AUTOSAR XML (schema 00044)
package /E40_Platform_System_SystemPackage/Components
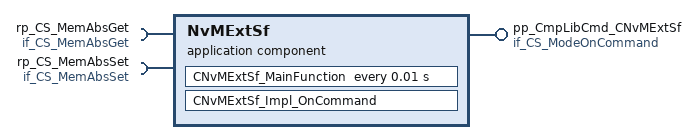
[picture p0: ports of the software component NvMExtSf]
  application sw component type NvMExtSf
    provide port pp_CmpLibCmd_CNvMExtSf: server-com-spec{operation=Impl_OnCommand, queue-length=1}, provided-interface=if_CS_ModeOnCommand
    require port rp_CS_MemAbsGet: required-com-specs=[Get_BsConst_Audio_Element, Get_BsConst_Communication_Element, Get_BsConst_EngOffTimer_Element, Get_BsConst_FuelGauge_Element, Get_BsConst_OilGauge_Element, Get_BsConst_PowerGauge_Element, Get_BsConst_Power_Element, Get_BsConst_RealTimeClock_Element, Get_BsConst_ServiceReminder_Element, Get_BsConst_SpeedoGauge_Element, Get_BsConst_TachoGauge_Element, Get_BsConst_TempGauge_Element, Get_BsConst_TripComputer_Element, Get_BsConst_Warning_Element, Get_BsCys_Certicificate_Element, Get_BsDiag_Dtc_Element, Get_BsDiag_ErrorRecord_Element, Get_BsReten_Audio_Element, Get_BsReten_Communication_Element, Get_BsReten_Display_Element, Get_BsReten_Gauges_Element, Get_BsReten_Illumination_Element, Get_BsReten_Odometer_Element, Get_BsReten_Personalization_Element, Get_BsReten_Power_Element, Get_BsReten_RealTimeClock_Element, Get_BsReten_Tripcomputer_Element, Get_BsReten_Warning_Element, Get_BsRt_CusDlt_Element, Get_BsRt_FuelGauge_Element, Get_BsRt_Illumination_Element, Get_BsRt_Odometer_Element, Get_BsRt_OilGauge_Element, Get_BsRt_Personalization_Element, Get_BsRt_PowerGauge_Element, Get_BsRt_RealTimeClock_Element, Get_BsRt_SpeedoGauge_Element, Get_BsRt_TachoGauge_Element, Get_BsRt_TempGauge_Element, Get_BsRt_TripComputer_Element, Get_BsRt_Warning_Element, Get_BsShare_EcuPartNumber_Element, Get_BsShare_SwUpdFotaFinPrint_Element, Get_BsShare_SwUpdFotaMode_Element, Get_BsShare_SwUpdFotaStatus_Element, Get_BsShare_SwUpdFotadecrypt_Element, Get_BsShare_SwUpdReflash_Element, Get_BsShare_VehicleConfig_Element, Get_BsShare_VisMeet_Element, Get_RefCys_Certicificate1_Element, Get_RefCys_Certicificate_Element, Get_BsShare_VisMeet_EOLEntry_Element, Get_BsShare_AssemblyManufacturingDate, Get_BsShare_AssemblyPlantNumber, Get_BsShare_HWModification, Get_BsShare_PCBSerialNumber, Get_BsShare_ProductSerialNumber, Get_BsShare_SMTManufacturingDate, Get_BsShare_SMTPlantNumber, Get_BsShare_VisteonPCBPartNumber, Get_BsShare_VisteonPartNumber], required-interface=if_CS_MemAbsGet
    require port rp_CS_MemAbsSet: required-com-specs=[Set_BsConst_Audio_Element, Set_BsConst_Communication_Element, Set_BsConst_EngOffTimer_Element, Set_BsConst_FuelGauge_Element, Set_BsConst_OilGauge_Element, Set_BsConst_PowerGauge_Element, Set_BsConst_Power_Element, Set_BsConst_RealTimeClock_Element, Set_BsConst_ServiceReminder_Element, Set_BsConst_SpeedoGauge_Element, Set_BsConst_TachoGauge_Element, Set_BsConst_TempGauge_Element, Set_BsConst_TripComputer_Element, Set_BsConst_Warning_Element, Set_BsCys_Certicificate_Element, Set_BsDiag_Dtc_Element, Set_BsDiag_ErrorRecord_Element, Set_BsReten_Audio_Element, Set_BsReten_Communication_Element, Set_BsReten_Display_Element, Set_BsReten_Gauges_Element, Set_BsReten_Illumination_Element, Set_BsReten_Odometer_Element, Set_BsReten_Personalization_Element, Set_BsReten_Power_Element, Set_BsReten_RealTimeClock_Element, Set_BsReten_Tripcomputer_Element, Set_BsReten_Warning_Element, Set_BsRt_CusDlt_Element, Set_BsRt_FuelGauge_Element, Set_BsRt_Illumination_Element, Set_BsRt_Odometer_Element, Set_BsRt_OilGauge_Element, Set_BsRt_Personalization_Element, Set_BsRt_PowerGauge_Element, Set_BsRt_RealTimeClock_Element, Set_BsRt_SpeedoGauge_Element, Set_BsRt_TachoGauge_Element, Set_BsRt_TempGauge_Element, Set_BsRt_TripComputer_Element, Set_BsRt_Warning_Element, Set_BsShare_EcuPartNumber_Element, Set_BsShare_SwUpdFotaFinPrint_Element, Set_BsShare_SwUpdFotaMode_Element, Set_BsShare_SwUpdFotaStatus_Element, Set_BsShare_SwUpdFotadecrypt_Element, Set_BsShare_SwUpdReflash_Element, Set_BsShare_VehicleConfig_Element, Set_BsShare_VisMeet_Element, Set_RefCys_Certicificate1_Element, Set_RefCys_Certicificate_Element, Set_BsShare_VisMeet_EOLEntry_Element, Set_BsShare_AssemblyManufacturingDate, Set_BsShare_AssemblyPlantNumber, Set_BsShare_HWModification, Set_BsShare_PCBSerialNumber, Set_BsShare_ProductSerialNumber, Set_BsShare_SMTManufacturingDate, Set_BsShare_SMTPlantNumber, Set_BsShare_VisteonPCBPartNumber, Set_BsShare_VisteonPartNumber], required-interface=if_CS_MemAbsSet
    behavior IB_NvMExtSf
      operation invoked event OIE_pp_CmpLibCmd_CNvMExtSf_CNvMExtSf_Impl_OnCommandTrigByImpl_OnCommand: start-on-event=CNvMExtSf_Impl_OnCommand, operation=pp_CmpLibCmd_CNvMExtSf.Impl_OnCommand
      timing event TECNvMExtSf_MainFunction: start-on-event=CNvMExtSf_MainFunction, period=0.01
      port-api-options:
        enable-take-address=false, indirect-api=false, port=pp_CmpLibCmd_CNvMExtSf
        enable-take-address=false, indirect-api=false, port=rp_CS_MemAbsGet
        enable-take-address=false, indirect-api=false, port=rp_CS_MemAbsSet
      runnable CNvMExtSf_Impl_OnCommand: can-be-invoked-concurrently=true
        138 x sync call:
          OA_rp_CS_MemAbsGet_Get_BsShare_SwUpdReflash_Element: operation=rp_CS_MemAbsGet.Get_BsShare_SwUpdReflash_Element
          OA_rp_CS_MemAbsGet_Get_BsShare_SwUpdFotaMode_Element: operation=rp_CS_MemAbsGet.Get_BsShare_SwUpdFotaMode_Element
          OA_rp_CS_MemAbsGet_Get_BsShare_SwUpdFotaFinPrint_Element: operation=rp_CS_MemAbsGet.Get_BsShare_SwUpdFotaFinPrint_Element
          OA_rp_CS_MemAbsGet_Get_BsShare_SwUpdFotaStatus_Element: operation=rp_CS_MemAbsGet.Get_BsShare_SwUpdFotaStatus_Element
          OA_rp_CS_MemAbsGet_Get_BsShare_SwUpdFotadecrypt_Element: operation=rp_CS_MemAbsGet.Get_BsShare_SwUpdFotadecrypt_Element
          OA_rp_CS_MemAbsGet_Get_BsShare_EcuPartNumber_Element: operation=rp_CS_MemAbsGet.Get_BsShare_EcuPartNumber_Element
          OA_rp_CS_MemAbsGet_Get_BsShare_VisteonPartNumber: operation=rp_CS_MemAbsGet.Get_BsShare_VisteonPartNumber
          OA_rp_CS_MemAbsGet_Get_BsShare_VisteonPCBPartNumber: operation=rp_CS_MemAbsGet.Get_BsShare_VisteonPCBPartNumber
          OA_rp_CS_MemAbsGet_Get_BsShare_ProductSerialNumber: operation=rp_CS_MemAbsGet.Get_BsShare_ProductSerialNumber
          OA_rp_CS_MemAbsGet_Get_BsShare_PCBSerialNumber: operation=rp_CS_MemAbsGet.Get_BsShare_PCBSerialNumber
          OA_rp_CS_MemAbsGet_Get_BsShare_SMTManufacturingDate: operation=rp_CS_MemAbsGet.Get_BsShare_SMTManufacturingDate
          OA_rp_CS_MemAbsGet_Get_BsShare_AssemblyManufacturingDate: operation=rp_CS_MemAbsGet.Get_BsShare_AssemblyManufacturingDate
          OA_rp_CS_MemAbsGet_Get_BsShare_SMTPlantNumber: operation=rp_CS_MemAbsGet.Get_BsShare_SMTPlantNumber
          OA_rp_CS_MemAbsGet_Get_BsShare_AssemblyPlantNumber: operation=rp_CS_MemAbsGet.Get_BsShare_AssemblyPlantNumber
          OA_rp_CS_MemAbsGet_Get_BsShare_HWModification: operation=rp_CS_MemAbsGet.Get_BsShare_HWModification
          OA_rp_CS_MemAbsGet_Get_BsShare_VisMeet_Element: operation=rp_CS_MemAbsGet.Get_BsShare_VisMeet_Element
          OA_rp_CS_MemAbsGet_Get_BsShare_VisMeet_EOLEntry_Element: operation=rp_CS_MemAbsGet.Get_BsShare_VisMeet_EOLEntry_Element
          OA_rp_CS_MemAbsGet_Get_BsShare_VehicleConfig_Element: operation=rp_CS_MemAbsGet.Get_BsShare_VehicleConfig_Element
          OA_rp_CS_MemAbsGet_Get_BsConst_SpeedoGauge_Element: operation=rp_CS_MemAbsGet.Get_BsConst_SpeedoGauge_Element
          OA_rp_CS_MemAbsGet_Get_BsConst_TachoGauge_Element: operation=rp_CS_MemAbsGet.Get_BsConst_TachoGauge_Element
          OA_rp_CS_MemAbsGet_Get_BsConst_FuelGauge_Element: operation=rp_CS_MemAbsGet.Get_BsConst_FuelGauge_Element
          OA_rp_CS_MemAbsGet_Get_BsConst_TempGauge_Element: operation=rp_CS_MemAbsGet.Get_BsConst_TempGauge_Element
          OA_rp_CS_MemAbsGet_Get_BsConst_PowerGauge_Element: operation=rp_CS_MemAbsGet.Get_BsConst_PowerGauge_Element
          OA_rp_CS_MemAbsGet_Get_BsConst_OilGauge_Element: operation=rp_CS_MemAbsGet.Get_BsConst_OilGauge_Element
          OA_rp_CS_MemAbsGet_Get_BsConst_TripComputer_Element: operation=rp_CS_MemAbsGet.Get_BsConst_TripComputer_Element
          OA_rp_CS_MemAbsGet_Get_BsConst_Illumination_Element: operation=rp_CS_MemAbsGet
          OA_rp_CS_MemAbsGet_Get_BsConst_Audio_Element: operation=rp_CS_MemAbsGet.Get_BsConst_Audio_Element
          OA_rp_CS_MemAbsGet_Get_BsConst_Warning_Element: operation=rp_CS_MemAbsGet.Get_BsConst_Warning_Element
          OA_rp_CS_MemAbsGet_Get_BsConst_RealTimeClock_Element: operation=rp_CS_MemAbsGet.Get_BsConst_RealTimeClock_Element
          OA_rp_CS_MemAbsGet_Get_BsConst_Communication_Element: operation=rp_CS_MemAbsGet.Get_BsConst_Communication_Element
          OA_rp_CS_MemAbsGet_Get_BsConst_Power_Element: operation=rp_CS_MemAbsGet.Get_BsConst_Power_Element
          OA_rp_CS_MemAbsGet_Get_BsConst_ServiceReminder_Element: operation=rp_CS_MemAbsGet.Get_BsConst_ServiceReminder_Element
          OA_rp_CS_MemAbsGet_Get_BsConst_EngOffTimer_Element: operation=rp_CS_MemAbsGet.Get_BsConst_EngOffTimer_Element
          OA_rp_CS_MemAbsGet_Get_BsFuSa_FeatureData_Warning_Element: operation=rp_CS_MemAbsGet
          OA_rp_CS_MemAbsGet_Get_BsFuSa_FeatureData_Power_Element: operation=rp_CS_MemAbsGet
          OA_rp_CS_MemAbsGet_Get_BsFuSa_FeatureData_Display_Element: operation=rp_CS_MemAbsGet
          OA_rp_CS_MemAbsGet_Get_BsFuSa_FeatureData_Audio_Element: operation=rp_CS_MemAbsGet
          OA_rp_CS_MemAbsGet_Get_BsFuSa_FeatureData_Communication_Element: operation=rp_CS_MemAbsGet
          OA_rp_CS_MemAbsGet_Get_BsFuSa_FeatureData_Fota_Element: operation=rp_CS_MemAbsGet
          OA_rp_CS_MemAbsGet_Get_BsCys_Certicificate_Element: operation=rp_CS_MemAbsGet.Get_BsCys_Certicificate_Element
          OA_rp_CS_MemAbsGet_Get_RefCys_Certicificate_Element: operation=rp_CS_MemAbsGet.Get_RefCys_Certicificate_Element
          OA_rp_CS_MemAbsGet_Get_RefCys_Certicificate1_Element: operation=rp_CS_MemAbsGet.Get_RefCys_Certicificate1_Element
          OA_rp_CS_MemAbsGet_Get_BsRt_Odometer_Element: operation=rp_CS_MemAbsGet.Get_BsRt_Odometer_Element
          OA_rp_CS_MemAbsGet_Get_BsRt_SpeedoGauge_Element: operation=rp_CS_MemAbsGet.Get_BsRt_SpeedoGauge_Element
          OA_rp_CS_MemAbsGet_Get_BsRt_TachoGauge_Element: operation=rp_CS_MemAbsGet.Get_BsRt_TachoGauge_Element
          OA_rp_CS_MemAbsGet_Get_BsRt_FuelGauge_Element: operation=rp_CS_MemAbsGet.Get_BsRt_FuelGauge_Element
          OA_rp_CS_MemAbsGet_Get_BsRt_TempGauge_Element: operation=rp_CS_MemAbsGet.Get_BsRt_TempGauge_Element
          OA_rp_CS_MemAbsGet_Get_BsRt_PowerGauge_Element: operation=rp_CS_MemAbsGet.Get_BsRt_PowerGauge_Element
          OA_rp_CS_MemAbsGet_Get_BsRt_OilGauge_Element: operation=rp_CS_MemAbsGet.Get_BsRt_OilGauge_Element
          OA_rp_CS_MemAbsGet_Get_BsRt_TripComputer_Element: operation=rp_CS_MemAbsGet.Get_BsRt_TripComputer_Element
          OA_rp_CS_MemAbsGet_Get_BsRt_Warning_Element: operation=rp_CS_MemAbsGet.Get_BsRt_Warning_Element
          OA_rp_CS_MemAbsGet_Get_BsRt_RealTimeClock_Element: operation=rp_CS_MemAbsGet.Get_BsRt_RealTimeClock_Element
          OA_rp_CS_MemAbsGet_Get_BsRt_Personalization_Element: operation=rp_CS_MemAbsGet.Get_BsRt_Personalization_Element
          OA_rp_CS_MemAbsGet_Get_BsRt_Illumination_Element: operation=rp_CS_MemAbsGet.Get_BsRt_Illumination_Element
          OA_rp_CS_MemAbsGet_Get_BsRt_CusDlt_Element: operation=rp_CS_MemAbsGet.Get_BsRt_CusDlt_Element
          OA_rp_CS_MemAbsGet_Get_BsReten_Odometer_Element: operation=rp_CS_MemAbsGet.Get_BsReten_Odometer_Element
          OA_rp_CS_MemAbsGet_Get_BsReten_Gauges_Element: operation=rp_CS_MemAbsGet.Get_BsReten_Gauges_Element
          OA_rp_CS_MemAbsGet_Get_BsReten_Tripcomputer_Element: operation=rp_CS_MemAbsGet.Get_BsReten_Tripcomputer_Element
          OA_rp_CS_MemAbsGet_Get_BsReten_Illumination_Element: operation=rp_CS_MemAbsGet.Get_BsReten_Illumination_Element
          OA_rp_CS_MemAbsGet_Get_BsReten_Audio_Element: operation=rp_CS_MemAbsGet.Get_BsReten_Audio_Element
          OA_rp_CS_MemAbsGet_Get_BsReten_Warning_Element: operation=rp_CS_MemAbsGet.Get_BsReten_Warning_Element
          OA_rp_CS_MemAbsGet_Get_BsReten_RealTimeClock_Element: operation=rp_CS_MemAbsGet.Get_BsReten_RealTimeClock_Element
          OA_rp_CS_MemAbsGet_Get_BsReten_Communication_Element: operation=rp_CS_MemAbsGet.Get_BsReten_Communication_Element
          OA_rp_CS_MemAbsGet_Get_BsReten_Personalization_Element: operation=rp_CS_MemAbsGet.Get_BsReten_Personalization_Element
          OA_rp_CS_MemAbsGet_Get_BsReten_VisDlt_Element: operation=rp_CS_MemAbsGet
          OA_rp_CS_MemAbsGet_Get_BsReten_Power_Element: operation=rp_CS_MemAbsGet.Get_BsReten_Power_Element
          OA_rp_CS_MemAbsGet_Get_BsReten_Display_Element: operation=rp_CS_MemAbsGet.Get_BsReten_Display_Element
          OA_rp_CS_MemAbsGet_Get_BsDiag_ErrorRecord_Element: operation=rp_CS_MemAbsGet.Get_BsDiag_ErrorRecord_Element
          OA_rp_CS_MemAbsGet_Get_BsDiag_Dtc_Element: operation=rp_CS_MemAbsGet.Get_BsDiag_Dtc_Element
          OA_rp_CS_MemAbsSet_Set_BsShare_SwUpdReflash_Element: operation=rp_CS_MemAbsSet.Set_BsShare_SwUpdReflash_Element
          OA_rp_CS_MemAbsSet_Set_BsShare_SwUpdFotaMode_Element: operation=rp_CS_MemAbsSet.Set_BsShare_SwUpdFotaMode_Element
          OA_rp_CS_MemAbsSet_Set_BsShare_SwUpdFotaFinPrint_Element: operation=rp_CS_MemAbsSet.Set_BsShare_SwUpdFotaFinPrint_Element
          OA_rp_CS_MemAbsSet_Set_BsShare_SwUpdFotaStatus_Element: operation=rp_CS_MemAbsSet.Set_BsShare_SwUpdFotaStatus_Element
          OA_rp_CS_MemAbsSet_Set_BsShare_SwUpdFotadecrypt_Element: operation=rp_CS_MemAbsSet.Set_BsShare_SwUpdFotadecrypt_Element
          OA_rp_CS_MemAbsSet_Set_BsShare_EcuPartNumber_Element: operation=rp_CS_MemAbsSet.Set_BsShare_EcuPartNumber_Element
          OA_rp_CS_MemAbsSet_Set_BsShare_VisteonPartNumber: operation=rp_CS_MemAbsSet.Set_BsShare_VisteonPartNumber
          OA_rp_CS_MemAbsSet_Set_BsShare_VisteonPCBPartNumber: operation=rp_CS_MemAbsSet.Set_BsShare_VisteonPCBPartNumber
          OA_rp_CS_MemAbsSet_Set_BsShare_ProductSerialNumber: operation=rp_CS_MemAbsSet.Set_BsShare_ProductSerialNumber
          OA_rp_CS_MemAbsSet_Set_BsShare_PCBSerialNumber: operation=rp_CS_MemAbsSet.Set_BsShare_PCBSerialNumber
          OA_rp_CS_MemAbsSet_Set_BsShare_SMTManufacturingDate: operation=rp_CS_MemAbsSet.Set_BsShare_SMTManufacturingDate
          OA_rp_CS_MemAbsSet_Set_BsShare_AssemblyManufacturingDate: operation=rp_CS_MemAbsSet.Set_BsShare_AssemblyManufacturingDate
          OA_rp_CS_MemAbsSet_Set_BsShare_SMTPlantNumber: operation=rp_CS_MemAbsSet.Set_BsShare_SMTPlantNumber
          OA_rp_CS_MemAbsSet_Set_BsShare_AssemblyPlantNumber: operation=rp_CS_MemAbsSet.Set_BsShare_AssemblyPlantNumber
          OA_rp_CS_MemAbsSet_Set_BsShare_HWModification: operation=rp_CS_MemAbsSet.Set_BsShare_HWModification
          OA_rp_CS_MemAbsSet_Set_BsShare_VisMeet_Element: operation=rp_CS_MemAbsSet.Set_BsShare_VisMeet_Element
          OA_rp_CS_MemAbsSet_Set_BsShare_VisMeet_EOLEntry_Element: operation=rp_CS_MemAbsSet.Set_BsShare_VisMeet_EOLEntry_Element
          OA_rp_CS_MemAbsSet_Set_BsShare_VehicleConfig_Element: operation=rp_CS_MemAbsSet.Set_BsShare_VehicleConfig_Element
          OA_rp_CS_MemAbsSet_Set_BsConst_SpeedoGauge_Element: operation=rp_CS_MemAbsSet.Set_BsConst_SpeedoGauge_Element
          OA_rp_CS_MemAbsSet_Set_BsConst_TachoGauge_Element: operation=rp_CS_MemAbsSet.Set_BsConst_TachoGauge_Element
          OA_rp_CS_MemAbsSet_Set_BsConst_FuelGauge_Element: operation=rp_CS_MemAbsSet.Set_BsConst_FuelGauge_Element
          OA_rp_CS_MemAbsSet_Set_BsConst_TempGauge_Element: operation=rp_CS_MemAbsSet.Set_BsConst_TempGauge_Element
          OA_rp_CS_MemAbsSet_Set_BsConst_PowerGauge_Element: operation=rp_CS_MemAbsSet.Set_BsConst_PowerGauge_Element
          OA_rp_CS_MemAbsSet_Set_BsConst_OilGauge_Element: operation=rp_CS_MemAbsSet.Set_BsConst_OilGauge_Element
          OA_rp_CS_MemAbsSet_Set_BsConst_TripComputer_Element: operation=rp_CS_MemAbsSet.Set_BsConst_TripComputer_Element
          OA_rp_CS_MemAbsSet_Set_BsConst_Illumination_Element: operation=rp_CS_MemAbsSet
          OA_rp_CS_MemAbsSet_Set_BsConst_Audio_Element: operation=rp_CS_MemAbsSet.Set_BsConst_Audio_Element
          OA_rp_CS_MemAbsSet_Set_BsConst_Warning_Element: operation=rp_CS_MemAbsSet.Set_BsConst_Warning_Element
          OA_rp_CS_MemAbsSet_Set_BsConst_RealTimeClock_Element: operation=rp_CS_MemAbsSet.Set_BsConst_RealTimeClock_Element
          OA_rp_CS_MemAbsSet_Set_BsConst_Communication_Element: operation=rp_CS_MemAbsSet.Set_BsConst_Communication_Element
          OA_rp_CS_MemAbsSet_Set_BsConst_Power_Element: operation=rp_CS_MemAbsSet.Set_BsConst_Power_Element
          OA_rp_CS_MemAbsSet_Set_BsConst_ServiceReminder_Element: operation=rp_CS_MemAbsSet.Set_BsConst_ServiceReminder_Element
          OA_rp_CS_MemAbsSet_Set_BsConst_EngOffTimer_Element: operation=rp_CS_MemAbsSet.Set_BsConst_EngOffTimer_Element
          OA_rp_CS_MemAbsSet_Set_BsFuSa_FeatureData_Warning_Element: operation=rp_CS_MemAbsSet
          OA_rp_CS_MemAbsSet_Set_BsFuSa_FeatureData_Power_Element: operation=rp_CS_MemAbsSet
          OA_rp_CS_MemAbsSet_Set_BsFuSa_FeatureData_Display_Element: operation=rp_CS_MemAbsSet
          OA_rp_CS_MemAbsSet_Set_BsFuSa_FeatureData_Audio_Element: operation=rp_CS_MemAbsSet
          OA_rp_CS_MemAbsSet_Set_BsFuSa_FeatureData_Communication_Element: operation=rp_CS_MemAbsSet
          OA_rp_CS_MemAbsSet_Set_BsFuSa_FeatureData_Fota_Element: operation=rp_CS_MemAbsSet
          OA_rp_CS_MemAbsSet_Set_BsCys_Certicificate_Element: operation=rp_CS_MemAbsSet.Set_BsCys_Certicificate_Element
          OA_rp_CS_MemAbsSet_Set_RefCys_Certicificate_Element: operation=rp_CS_MemAbsSet.Set_RefCys_Certicificate_Element
          OA_rp_CS_MemAbsSet_Set_RefCys_Certicificate1_Element: operation=rp_CS_MemAbsSet.Set_RefCys_Certicificate1_Element
          OA_rp_CS_MemAbsSet_Set_BsRt_Odometer_Element: operation=rp_CS_MemAbsSet.Set_BsRt_Odometer_Element
          OA_rp_CS_MemAbsSet_Set_BsRt_SpeedoGauge_Element: operation=rp_CS_MemAbsSet.Set_BsRt_SpeedoGauge_Element
          OA_rp_CS_MemAbsSet_Set_BsRt_TachoGauge_Element: operation=rp_CS_MemAbsSet.Set_BsRt_TachoGauge_Element
          OA_rp_CS_MemAbsSet_Set_BsRt_FuelGauge_Element: operation=rp_CS_MemAbsSet.Set_BsRt_FuelGauge_Element
          OA_rp_CS_MemAbsSet_Set_BsRt_TempGauge_Element: operation=rp_CS_MemAbsSet.Set_BsRt_TempGauge_Element
          OA_rp_CS_MemAbsSet_Set_BsRt_PowerGauge_Element: operation=rp_CS_MemAbsSet.Set_BsRt_PowerGauge_Element
          OA_rp_CS_MemAbsSet_Set_BsRt_OilGauge_Element: operation=rp_CS_MemAbsSet.Set_BsRt_OilGauge_Element
          OA_rp_CS_MemAbsSet_Set_BsRt_TripComputer_Element: operation=rp_CS_MemAbsSet.Set_BsRt_TripComputer_Element
          OA_rp_CS_MemAbsSet_Set_BsRt_Warning_Element: operation=rp_CS_MemAbsSet.Set_BsRt_Warning_Element
          OA_rp_CS_MemAbsSet_Set_BsRt_RealTimeClock_Element: operation=rp_CS_MemAbsSet.Set_BsRt_RealTimeClock_Element
          OA_rp_CS_MemAbsSet_Set_BsRt_Personalization_Element: operation=rp_CS_MemAbsSet.Set_BsRt_Personalization_Element
          OA_rp_CS_MemAbsSet_Set_BsRt_Illumination_Element: operation=rp_CS_MemAbsSet.Set_BsRt_Illumination_Element
          OA_rp_CS_MemAbsSet_Set_BsRt_CusDlt_Element: operation=rp_CS_MemAbsSet.Set_BsRt_CusDlt_Element
          OA_rp_CS_MemAbsSet_Set_BsReten_Odometer_Element: operation=rp_CS_MemAbsSet.Set_BsReten_Odometer_Element
          OA_rp_CS_MemAbsSet_Set_BsReten_Gauges_Element: operation=rp_CS_MemAbsSet.Set_BsReten_Gauges_Element
          OA_rp_CS_MemAbsSet_Set_BsReten_Tripcomputer_Element: operation=rp_CS_MemAbsSet.Set_BsReten_Tripcomputer_Element
          OA_rp_CS_MemAbsSet_Set_BsReten_Illumination_Element: operation=rp_CS_MemAbsSet.Set_BsReten_Illumination_Element
          OA_rp_CS_MemAbsSet_Set_BsReten_Audio_Element: operation=rp_CS_MemAbsSet.Set_BsReten_Audio_Element
          OA_rp_CS_MemAbsSet_Set_BsReten_Warning_Element: operation=rp_CS_MemAbsSet.Set_BsReten_Warning_Element
          OA_rp_CS_MemAbsSet_Set_BsReten_RealTimeClock_Element: operation=rp_CS_MemAbsSet.Set_BsReten_RealTimeClock_Element
          OA_rp_CS_MemAbsSet_Set_BsReten_Communication_Element: operation=rp_CS_MemAbsSet.Set_BsReten_Communication_Element
          OA_rp_CS_MemAbsSet_Set_BsReten_Personalization_Element: operation=rp_CS_MemAbsSet.Set_BsReten_Personalization_Element
          OA_rp_CS_MemAbsSet_Set_BsReten_VisDlt_Element: operation=rp_CS_MemAbsSet
          OA_rp_CS_MemAbsSet_Set_BsReten_Power_Element: operation=rp_CS_MemAbsSet.Set_BsReten_Power_Element
          OA_rp_CS_MemAbsSet_Set_BsReten_Display_Element: operation=rp_CS_MemAbsSet.Set_BsReten_Display_Element
          OA_rp_CS_MemAbsSet_Set_BsDiag_ErrorRecord_Element: operation=rp_CS_MemAbsSet.Set_BsDiag_ErrorRecord_Element
          OA_rp_CS_MemAbsSet_Set_BsDiag_Dtc_Element: operation=rp_CS_MemAbsSet.Set_BsDiag_Dtc_Element
      runnable CNvMExtSf_MainFunction: can-be-invoked-concurrently=true
        138 x sync call:
          OA_rp_CS_MemAbsGet_Get_BsShare_SwUpdReflash_Element: operation=rp_CS_MemAbsGet.Get_BsShare_SwUpdReflash_Element
          OA_rp_CS_MemAbsGet_Get_BsShare_SwUpdFotaMode_Element: operation=rp_CS_MemAbsGet.Get_BsShare_SwUpdFotaMode_Element
          OA_rp_CS_MemAbsGet_Get_BsShare_SwUpdFotaFinPrint_Element: operation=rp_CS_MemAbsGet.Get_BsShare_SwUpdFotaFinPrint_Element
          OA_rp_CS_MemAbsGet_Get_BsShare_SwUpdFotaStatus_Element: operation=rp_CS_MemAbsGet.Get_BsShare_SwUpdFotaStatus_Element
          OA_rp_CS_MemAbsGet_Get_BsShare_SwUpdFotadecrypt_Element: operation=rp_CS_MemAbsGet.Get_BsShare_SwUpdFotadecrypt_Element
          OA_rp_CS_MemAbsGet_Get_BsShare_EcuPartNumber_Element: operation=rp_CS_MemAbsGet.Get_BsShare_EcuPartNumber_Element
          OA_rp_CS_MemAbsGet_Get_BsShare_VisteonPartNumber: operation=rp_CS_MemAbsGet.Get_BsShare_VisteonPartNumber
          OA_rp_CS_MemAbsGet_Get_BsShare_VisteonPCBPartNumber: operation=rp_CS_MemAbsGet.Get_BsShare_VisteonPCBPartNumber
          OA_rp_CS_MemAbsGet_Get_BsShare_ProductSerialNumber: operation=rp_CS_MemAbsGet.Get_BsShare_ProductSerialNumber
          OA_rp_CS_MemAbsGet_Get_BsShare_PCBSerialNumber: operation=rp_CS_MemAbsGet.Get_BsShare_PCBSerialNumber
          OA_rp_CS_MemAbsGet_Get_BsShare_SMTManufacturingDate: operation=rp_CS_MemAbsGet.Get_BsShare_SMTManufacturingDate
          OA_rp_CS_MemAbsGet_Get_BsShare_AssemblyManufacturingDate: operation=rp_CS_MemAbsGet.Get_BsShare_AssemblyManufacturingDate
          OA_rp_CS_MemAbsGet_Get_BsShare_SMTPlantNumber: operation=rp_CS_MemAbsGet.Get_BsShare_SMTPlantNumber
          OA_rp_CS_MemAbsGet_Get_BsShare_AssemblyPlantNumber: operation=rp_CS_MemAbsGet.Get_BsShare_AssemblyPlantNumber
          OA_rp_CS_MemAbsGet_Get_BsShare_HWModification: operation=rp_CS_MemAbsGet.Get_BsShare_HWModification
          OA_rp_CS_MemAbsGet_Get_BsShare_VisMeet_Element: operation=rp_CS_MemAbsGet.Get_BsShare_VisMeet_Element
          OA_rp_CS_MemAbsGet_Get_BsShare_VisMeet_EOLEntry_Element: operation=rp_CS_MemAbsGet.Get_BsShare_VisMeet_EOLEntry_Element
          OA_rp_CS_MemAbsGet_Get_BsShare_VehicleConfig_Element: operation=rp_CS_MemAbsGet.Get_BsShare_VehicleConfig_Element
          OA_rp_CS_MemAbsGet_Get_BsConst_SpeedoGauge_Element: operation=rp_CS_MemAbsGet.Get_BsConst_SpeedoGauge_Element
          OA_rp_CS_MemAbsGet_Get_BsConst_TachoGauge_Element: operation=rp_CS_MemAbsGet.Get_BsConst_TachoGauge_Element
          OA_rp_CS_MemAbsGet_Get_BsConst_FuelGauge_Element: operation=rp_CS_MemAbsGet.Get_BsConst_FuelGauge_Element
          OA_rp_CS_MemAbsGet_Get_BsConst_TempGauge_Element: operation=rp_CS_MemAbsGet.Get_BsConst_TempGauge_Element
          OA_rp_CS_MemAbsGet_Get_BsConst_PowerGauge_Element: operation=rp_CS_MemAbsGet.Get_BsConst_PowerGauge_Element
          OA_rp_CS_MemAbsGet_Get_BsConst_OilGauge_Element: operation=rp_CS_MemAbsGet.Get_BsConst_OilGauge_Element
          OA_rp_CS_MemAbsGet_Get_BsConst_TripComputer_Element: operation=rp_CS_MemAbsGet.Get_BsConst_TripComputer_Element
          OA_rp_CS_MemAbsGet_Get_BsConst_Illumination_Element: operation=rp_CS_MemAbsGet
          OA_rp_CS_MemAbsGet_Get_BsConst_Audio_Element: operation=rp_CS_MemAbsGet.Get_BsConst_Audio_Element
          OA_rp_CS_MemAbsGet_Get_BsConst_Warning_Element: operation=rp_CS_MemAbsGet.Get_BsConst_Warning_Element
          OA_rp_CS_MemAbsGet_Get_BsConst_RealTimeClock_Element: operation=rp_CS_MemAbsGet.Get_BsConst_RealTimeClock_Element
          OA_rp_CS_MemAbsGet_Get_BsConst_Communication_Element: operation=rp_CS_MemAbsGet.Get_BsConst_Communication_Element
          OA_rp_CS_MemAbsGet_Get_BsConst_Power_Element: operation=rp_CS_MemAbsGet.Get_BsConst_Power_Element
          OA_rp_CS_MemAbsGet_Get_BsConst_ServiceReminder_Element: operation=rp_CS_MemAbsGet.Get_BsConst_ServiceReminder_Element
          OA_rp_CS_MemAbsGet_Get_BsConst_EngOffTimer_Element: operation=rp_CS_MemAbsGet.Get_BsConst_EngOffTimer_Element
          OA_rp_CS_MemAbsGet_Get_BsFuSa_FeatureData_Warning_Element: operation=rp_CS_MemAbsGet
          OA_rp_CS_MemAbsGet_Get_BsFuSa_FeatureData_Power_Element: operation=rp_CS_MemAbsGet
          OA_rp_CS_MemAbsGet_Get_BsFuSa_FeatureData_Display_Element: operation=rp_CS_MemAbsGet
          OA_rp_CS_MemAbsGet_Get_BsFuSa_FeatureData_Audio_Element: operation=rp_CS_MemAbsGet
          OA_rp_CS_MemAbsGet_Get_BsFuSa_FeatureData_Communication_Element: operation=rp_CS_MemAbsGet
          OA_rp_CS_MemAbsGet_Get_BsFuSa_FeatureData_Fota_Element: operation=rp_CS_MemAbsGet
          OA_rp_CS_MemAbsGet_Get_BsCys_Certicificate_Element: operation=rp_CS_MemAbsGet.Get_BsCys_Certicificate_Element
          OA_rp_CS_MemAbsGet_Get_RefCys_Certicificate_Element: operation=rp_CS_MemAbsGet.Get_RefCys_Certicificate_Element
          OA_rp_CS_MemAbsGet_Get_RefCys_Certicificate1_Element: operation=rp_CS_MemAbsGet.Get_RefCys_Certicificate1_Element
          OA_rp_CS_MemAbsGet_Get_BsRt_Odometer_Element: operation=rp_CS_MemAbsGet.Get_BsRt_Odometer_Element
          OA_rp_CS_MemAbsGet_Get_BsRt_SpeedoGauge_Element: operation=rp_CS_MemAbsGet.Get_BsRt_SpeedoGauge_Element
          OA_rp_CS_MemAbsGet_Get_BsRt_TachoGauge_Element: operation=rp_CS_MemAbsGet.Get_BsRt_TachoGauge_Element
          OA_rp_CS_MemAbsGet_Get_BsRt_FuelGauge_Element: operation=rp_CS_MemAbsGet.Get_BsRt_FuelGauge_Element
          OA_rp_CS_MemAbsGet_Get_BsRt_TempGauge_Element: operation=rp_CS_MemAbsGet.Get_BsRt_TempGauge_Element
          OA_rp_CS_MemAbsGet_Get_BsRt_PowerGauge_Element: operation=rp_CS_MemAbsGet.Get_BsRt_PowerGauge_Element
          OA_rp_CS_MemAbsGet_Get_BsRt_OilGauge_Element: operation=rp_CS_MemAbsGet.Get_BsRt_OilGauge_Element
          OA_rp_CS_MemAbsGet_Get_BsRt_TripComputer_Element: operation=rp_CS_MemAbsGet.Get_BsRt_TripComputer_Element
          OA_rp_CS_MemAbsGet_Get_BsRt_Warning_Element: operation=rp_CS_MemAbsGet.Get_BsRt_Warning_Element
          OA_rp_CS_MemAbsGet_Get_BsRt_RealTimeClock_Element: operation=rp_CS_MemAbsGet.Get_BsRt_RealTimeClock_Element
          OA_rp_CS_MemAbsGet_Get_BsRt_Personalization_Element: operation=rp_CS_MemAbsGet.Get_BsRt_Personalization_Element
          OA_rp_CS_MemAbsGet_Get_BsRt_Illumination_Element: operation=rp_CS_MemAbsGet.Get_BsRt_Illumination_Element
          OA_rp_CS_MemAbsGet_Get_BsRt_CusDlt_Element: operation=rp_CS_MemAbsGet.Get_BsRt_CusDlt_Element
          OA_rp_CS_MemAbsGet_Get_BsReten_Odometer_Element: operation=rp_CS_MemAbsGet.Get_BsReten_Odometer_Element
          OA_rp_CS_MemAbsGet_Get_BsReten_Gauges_Element: operation=rp_CS_MemAbsGet.Get_BsReten_Gauges_Element
          OA_rp_CS_MemAbsGet_Get_BsReten_Tripcomputer_Element: operation=rp_CS_MemAbsGet.Get_BsReten_Tripcomputer_Element
          OA_rp_CS_MemAbsGet_Get_BsReten_Illumination_Element: operation=rp_CS_MemAbsGet.Get_BsReten_Illumination_Element
          OA_rp_CS_MemAbsGet_Get_BsReten_Audio_Element: operation=rp_CS_MemAbsGet.Get_BsReten_Audio_Element
          OA_rp_CS_MemAbsGet_Get_BsReten_Warning_Element: operation=rp_CS_MemAbsGet.Get_BsReten_Warning_Element
          OA_rp_CS_MemAbsGet_Get_BsReten_RealTimeClock_Element: operation=rp_CS_MemAbsGet.Get_BsReten_RealTimeClock_Element
          OA_rp_CS_MemAbsGet_Get_BsReten_Communication_Element: operation=rp_CS_MemAbsGet.Get_BsReten_Communication_Element
          OA_rp_CS_MemAbsGet_Get_BsReten_Personalization_Element: operation=rp_CS_MemAbsGet.Get_BsReten_Personalization_Element
          OA_rp_CS_MemAbsGet_Get_BsReten_VisDlt_Element: operation=rp_CS_MemAbsGet
          OA_rp_CS_MemAbsGet_Get_BsReten_Power_Element: operation=rp_CS_MemAbsGet.Get_BsReten_Power_Element
          OA_rp_CS_MemAbsGet_Get_BsReten_Display_Element: operation=rp_CS_MemAbsGet.Get_BsReten_Display_Element
          OA_rp_CS_MemAbsGet_Get_BsDiag_ErrorRecord_Element: operation=rp_CS_MemAbsGet.Get_BsDiag_ErrorRecord_Element
          OA_rp_CS_MemAbsGet_Get_BsDiag_Dtc_Element: operation=rp_CS_MemAbsGet.Get_BsDiag_Dtc_Element
          OA_rp_CS_MemAbsSet_Set_BsShare_SwUpdReflash_Element: operation=rp_CS_MemAbsSet.Set_BsShare_SwUpdReflash_Element
          OA_rp_CS_MemAbsSet_Set_BsShare_SwUpdFotaMode_Element: operation=rp_CS_MemAbsSet.Set_BsShare_SwUpdFotaMode_Element
          OA_rp_CS_MemAbsSet_Set_BsShare_SwUpdFotaFinPrint_Element: operation=rp_CS_MemAbsSet.Set_BsShare_SwUpdFotaFinPrint_Element
          OA_rp_CS_MemAbsSet_Set_BsShare_SwUpdFotaStatus_Element: operation=rp_CS_MemAbsSet.Set_BsShare_SwUpdFotaStatus_Element
          OA_rp_CS_MemAbsSet_Set_BsShare_SwUpdFotadecrypt_Element: operation=rp_CS_MemAbsSet.Set_BsShare_SwUpdFotadecrypt_Element
          OA_rp_CS_MemAbsSet_Set_BsShare_EcuPartNumber_Element: operation=rp_CS_MemAbsSet.Set_BsShare_EcuPartNumber_Element
          OA_rp_CS_MemAbsSet_Set_BsShare_VisteonPartNumber: operation=rp_CS_MemAbsSet.Set_BsShare_VisteonPartNumber
          OA_rp_CS_MemAbsSet_Set_BsShare_VisteonPCBPartNumber: operation=rp_CS_MemAbsSet.Set_BsShare_VisteonPCBPartNumber
          OA_rp_CS_MemAbsSet_Set_BsShare_ProductSerialNumber: operation=rp_CS_MemAbsSet.Set_BsShare_ProductSerialNumber
          OA_rp_CS_MemAbsSet_Set_BsShare_PCBSerialNumber: operation=rp_CS_MemAbsSet.Set_BsShare_PCBSerialNumber
          OA_rp_CS_MemAbsSet_Set_BsShare_SMTManufacturingDate: operation=rp_CS_MemAbsSet.Set_BsShare_SMTManufacturingDate
          OA_rp_CS_MemAbsSet_Set_BsShare_AssemblyManufacturingDate: operation=rp_CS_MemAbsSet.Set_BsShare_AssemblyManufacturingDate
          OA_rp_CS_MemAbsSet_Set_BsShare_SMTPlantNumber: operation=rp_CS_MemAbsSet.Set_BsShare_SMTPlantNumber
          OA_rp_CS_MemAbsSet_Set_BsShare_AssemblyPlantNumber: operation=rp_CS_MemAbsSet.Set_BsShare_AssemblyPlantNumber
          OA_rp_CS_MemAbsSet_Set_BsShare_HWModification: operation=rp_CS_MemAbsSet.Set_BsShare_HWModification
          OA_rp_CS_MemAbsSet_Set_BsShare_VisMeet_Element: operation=rp_CS_MemAbsSet.Set_BsShare_VisMeet_Element
          OA_rp_CS_MemAbsSet_Set_BsShare_VisMeet_EOLEntry_Element: operation=rp_CS_MemAbsSet.Set_BsShare_VisMeet_EOLEntry_Element
          OA_rp_CS_MemAbsSet_Set_BsShare_VehicleConfig_Element: operation=rp_CS_MemAbsSet.Set_BsShare_VehicleConfig_Element
          OA_rp_CS_MemAbsSet_Set_BsConst_SpeedoGauge_Element: operation=rp_CS_MemAbsSet.Set_BsConst_SpeedoGauge_Element
          OA_rp_CS_MemAbsSet_Set_BsConst_TachoGauge_Element: operation=rp_CS_MemAbsSet.Set_BsConst_TachoGauge_Element
          OA_rp_CS_MemAbsSet_Set_BsConst_FuelGauge_Element: operation=rp_CS_MemAbsSet.Set_BsConst_FuelGauge_Element
          OA_rp_CS_MemAbsSet_Set_BsConst_TempGauge_Element: operation=rp_CS_MemAbsSet.Set_BsConst_TempGauge_Element
          OA_rp_CS_MemAbsSet_Set_BsConst_PowerGauge_Element: operation=rp_CS_MemAbsSet.Set_BsConst_PowerGauge_Element
          OA_rp_CS_MemAbsSet_Set_BsConst_OilGauge_Element: operation=rp_CS_MemAbsSet.Set_BsConst_OilGauge_Element
          OA_rp_CS_MemAbsSet_Set_BsConst_TripComputer_Element: operation=rp_CS_MemAbsSet.Set_BsConst_TripComputer_Element
          OA_rp_CS_MemAbsSet_Set_BsConst_Illumination_Element: operation=rp_CS_MemAbsSet
          OA_rp_CS_MemAbsSet_Set_BsConst_Audio_Element: operation=rp_CS_MemAbsSet.Set_BsConst_Audio_Element
          OA_rp_CS_MemAbsSet_Set_BsConst_Warning_Element: operation=rp_CS_MemAbsSet.Set_BsConst_Warning_Element
          OA_rp_CS_MemAbsSet_Set_BsConst_RealTimeClock_Element: operation=rp_CS_MemAbsSet.Set_BsConst_RealTimeClock_Element
          OA_rp_CS_MemAbsSet_Set_BsConst_Communication_Element: operation=rp_CS_MemAbsSet.Set_BsConst_Communication_Element
          OA_rp_CS_MemAbsSet_Set_BsConst_Power_Element: operation=rp_CS_MemAbsSet.Set_BsConst_Power_Element
          OA_rp_CS_MemAbsSet_Set_BsConst_ServiceReminder_Element: operation=rp_CS_MemAbsSet.Set_BsConst_ServiceReminder_Element
          OA_rp_CS_MemAbsSet_Set_BsConst_EngOffTimer_Element: operation=rp_CS_MemAbsSet.Set_BsConst_EngOffTimer_Element
          OA_rp_CS_MemAbsSet_Set_BsFuSa_FeatureData_Warning_Element: operation=rp_CS_MemAbsSet
          OA_rp_CS_MemAbsSet_Set_BsFuSa_FeatureData_Power_Element: operation=rp_CS_MemAbsSet
          OA_rp_CS_MemAbsSet_Set_BsFuSa_FeatureData_Display_Element: operation=rp_CS_MemAbsSet
          OA_rp_CS_MemAbsSet_Set_BsFuSa_FeatureData_Audio_Element: operation=rp_CS_MemAbsSet
          OA_rp_CS_MemAbsSet_Set_BsFuSa_FeatureData_Communication_Element: operation=rp_CS_MemAbsSet
          OA_rp_CS_MemAbsSet_Set_BsFuSa_FeatureData_Fota_Element: operation=rp_CS_MemAbsSet
          OA_rp_CS_MemAbsSet_Set_BsCys_Certicificate_Element: operation=rp_CS_MemAbsSet.Set_BsCys_Certicificate_Element
          OA_rp_CS_MemAbsSet_Set_RefCys_Certicificate_Element: operation=rp_CS_MemAbsSet.Set_RefCys_Certicificate_Element
          OA_rp_CS_MemAbsSet_Set_RefCys_Certicificate1_Element: operation=rp_CS_MemAbsSet.Set_RefCys_Certicificate1_Element
          OA_rp_CS_MemAbsSet_Set_BsRt_Odometer_Element: operation=rp_CS_MemAbsSet.Set_BsRt_Odometer_Element
          OA_rp_CS_MemAbsSet_Set_BsRt_SpeedoGauge_Element: operation=rp_CS_MemAbsSet.Set_BsRt_SpeedoGauge_Element
          OA_rp_CS_MemAbsSet_Set_BsRt_TachoGauge_Element: operation=rp_CS_MemAbsSet.Set_BsRt_TachoGauge_Element
          OA_rp_CS_MemAbsSet_Set_BsRt_FuelGauge_Element: operation=rp_CS_MemAbsSet.Set_BsRt_FuelGauge_Element
          OA_rp_CS_MemAbsSet_Set_BsRt_TempGauge_Element: operation=rp_CS_MemAbsSet.Set_BsRt_TempGauge_Element
          OA_rp_CS_MemAbsSet_Set_BsRt_PowerGauge_Element: operation=rp_CS_MemAbsSet.Set_BsRt_PowerGauge_Element
          OA_rp_CS_MemAbsSet_Set_BsRt_OilGauge_Element: operation=rp_CS_MemAbsSet.Set_BsRt_OilGauge_Element
          OA_rp_CS_MemAbsSet_Set_BsRt_TripComputer_Element: operation=rp_CS_MemAbsSet.Set_BsRt_TripComputer_Element
          OA_rp_CS_MemAbsSet_Set_BsRt_Warning_Element: operation=rp_CS_MemAbsSet.Set_BsRt_Warning_Element
          OA_rp_CS_MemAbsSet_Set_BsRt_RealTimeClock_Element: operation=rp_CS_MemAbsSet.Set_BsRt_RealTimeClock_Element
          OA_rp_CS_MemAbsSet_Set_BsRt_Personalization_Element: operation=rp_CS_MemAbsSet.Set_BsRt_Personalization_Element
          OA_rp_CS_MemAbsSet_Set_BsRt_Illumination_Element: operation=rp_CS_MemAbsSet.Set_BsRt_Illumination_Element
          OA_rp_CS_MemAbsSet_Set_BsRt_CusDlt_Element: operation=rp_CS_MemAbsSet.Set_BsRt_CusDlt_Element
          OA_rp_CS_MemAbsSet_Set_BsReten_Odometer_Element: operation=rp_CS_MemAbsSet.Set_BsReten_Odometer_Element
          OA_rp_CS_MemAbsSet_Set_BsReten_Gauges_Element: operation=rp_CS_MemAbsSet.Set_BsReten_Gauges_Element
          OA_rp_CS_MemAbsSet_Set_BsReten_Tripcomputer_Element: operation=rp_CS_MemAbsSet.Set_BsReten_Tripcomputer_Element
          OA_rp_CS_MemAbsSet_Set_BsReten_Illumination_Element: operation=rp_CS_MemAbsSet.Set_BsReten_Illumination_Element
          OA_rp_CS_MemAbsSet_Set_BsReten_Audio_Element: operation=rp_CS_MemAbsSet.Set_BsReten_Audio_Element
          OA_rp_CS_MemAbsSet_Set_BsReten_Warning_Element: operation=rp_CS_MemAbsSet.Set_BsReten_Warning_Element
          OA_rp_CS_MemAbsSet_Set_BsReten_RealTimeClock_Element: operation=rp_CS_MemAbsSet.Set_BsReten_RealTimeClock_Element
          OA_rp_CS_MemAbsSet_Set_BsReten_Communication_Element: operation=rp_CS_MemAbsSet.Set_BsReten_Communication_Element
          OA_rp_CS_MemAbsSet_Set_BsReten_Personalization_Element: operation=rp_CS_MemAbsSet.Set_BsReten_Personalization_Element
          OA_rp_CS_MemAbsSet_Set_BsReten_VisDlt_Element: operation=rp_CS_MemAbsSet
          OA_rp_CS_MemAbsSet_Set_BsReten_Power_Element: operation=rp_CS_MemAbsSet.Set_BsReten_Power_Element
          OA_rp_CS_MemAbsSet_Set_BsReten_Display_Element: operation=rp_CS_MemAbsSet.Set_BsReten_Display_Element
          OA_rp_CS_MemAbsSet_Set_BsDiag_ErrorRecord_Element: operation=rp_CS_MemAbsSet.Set_BsDiag_ErrorRecord_Element
          OA_rp_CS_MemAbsSet_Set_BsDiag_Dtc_Element: operation=rp_CS_MemAbsSet.Set_BsDiag_Dtc_Element
  swc implementation IMPL_NvMExtSf: behavior=IB_NvMExtSf
